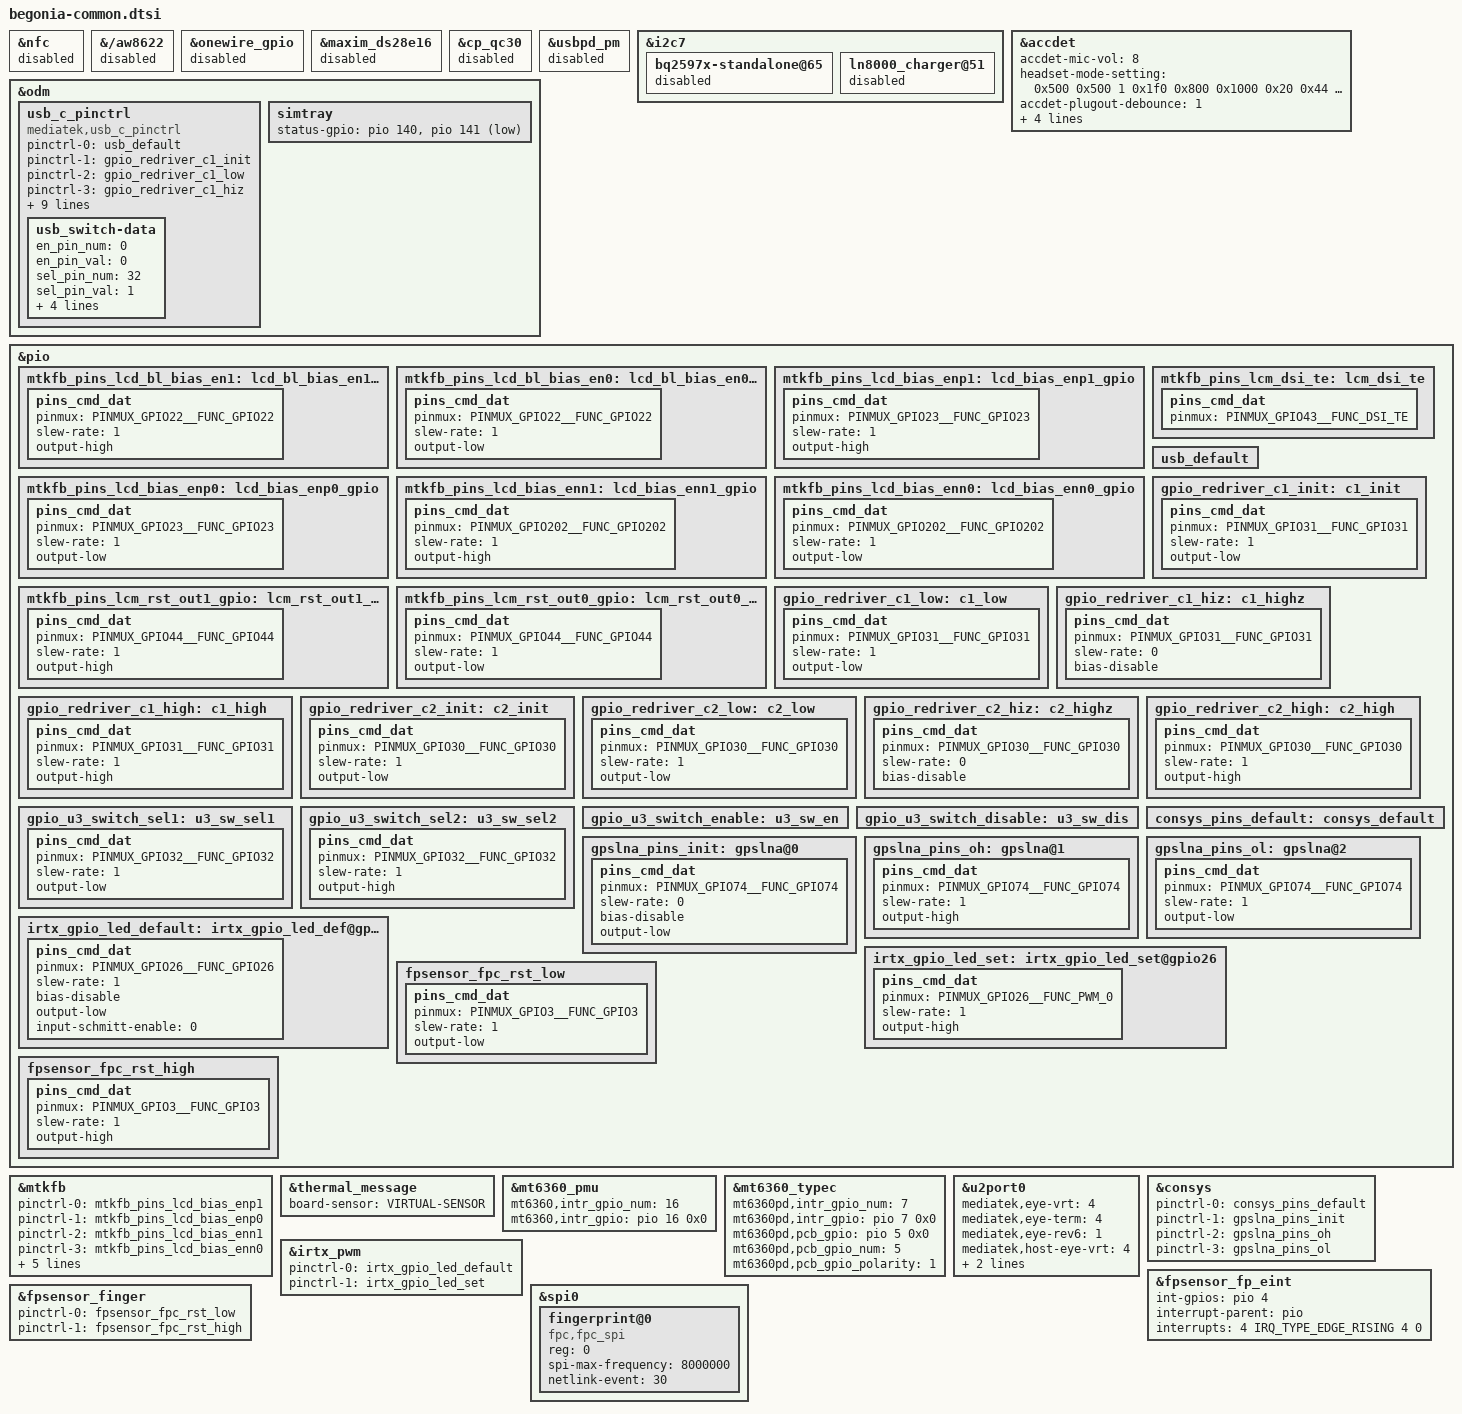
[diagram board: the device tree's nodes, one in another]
// SPDX-License-Identifier: GPL-2.0
#include <dt-bindings/interrupt-controller/irq.h>
#include <dt-bindings/interrupt-controller/arm-gic.h>
#include <dt-bindings/pinctrl/mt6785-pinfunc.h>

&nfc {
	status = "disabled";
};

&{/aw8622} {
	status = "disabled";
};

&onewire_gpio {
	status = "disabled";
};

&maxim_ds28e16 {
	status = "disabled";
};

&cp_qc30 {
	status = "disabled";
};

&usbpd_pm {
	status = "disabled";
};

&i2c7 {
	bq2597x-standalone@65 {
		status = "disabled";
	};

	ln8000_charger@51 {
		status = "disabled";
	};
};

&accdet {
	accdet-mic-vol = <8>;
	headset-mode-setting = <0x500 0x500 1 0x1f0
				0x800 0x1000 0x20 0x44
				0x4 0x1
				0x5 0x3 0x3 0x7 0xe>;
	accdet-plugout-debounce = <1>;
	accdet-mic-mode = <2>;
	headset-three-key-threshold = <0 80 220 400>;
	headset-four-key-threshold = <0 58 121 192 400>;
	eint_use_ext_res = <4>;
	status = "okay";
};

&odm {
	usb_c_pinctrl: usb_c_pinctrl {
		compatible = "mediatek,usb_c_pinctrl";
	};

	simtray {
		status-gpio = <&pio 140 0>,
			      <&pio 141 1>;
	};
};

&pio {
	mtkfb_pins_lcd_bl_bias_en1: lcd_bl_bias_en1_gpio {
		pins_cmd_dat {
			pinmux = <PINMUX_GPIO22__FUNC_GPIO22>;
			slew-rate = <1>;
			output-high;
		};
	};

	mtkfb_pins_lcd_bl_bias_en0: lcd_bl_bias_en0_gpio {
		pins_cmd_dat {
			pinmux = <PINMUX_GPIO22__FUNC_GPIO22>;
			slew-rate = <1>;
			output-low;
		};
	};

	mtkfb_pins_lcd_bias_enp1: lcd_bias_enp1_gpio {
		pins_cmd_dat {
			pinmux = <PINMUX_GPIO23__FUNC_GPIO23>;
			slew-rate = <1>;
			output-high;
		};
	};

	mtkfb_pins_lcd_bias_enp0: lcd_bias_enp0_gpio {
		pins_cmd_dat {
			pinmux = <PINMUX_GPIO23__FUNC_GPIO23>;
			slew-rate = <1>;
			output-low;
		};
	};

	mtkfb_pins_lcd_bias_enn1: lcd_bias_enn1_gpio {
		pins_cmd_dat {
			pinmux = <PINMUX_GPIO202__FUNC_GPIO202>;
			slew-rate = <1>;
			output-high;
		};
	};

	mtkfb_pins_lcd_bias_enn0: lcd_bias_enn0_gpio {
		pins_cmd_dat {
			pinmux = <PINMUX_GPIO202__FUNC_GPIO202>;
			slew-rate = <1>;
			output-low;
		};
	};

	mtkfb_pins_lcm_rst_out1_gpio: lcm_rst_out1_gpio {
		pins_cmd_dat {
			pinmux = <PINMUX_GPIO44__FUNC_GPIO44>;
			slew-rate = <1>;
			output-high;
		};
	};

	mtkfb_pins_lcm_rst_out0_gpio: lcm_rst_out0_gpio {
		pins_cmd_dat {
			pinmux = <PINMUX_GPIO44__FUNC_GPIO44>;
			slew-rate = <1>;
			output-low;
		};
	};

	mtkfb_pins_lcm_dsi_te: lcm_dsi_te {
		pins_cmd_dat {
			pinmux = <PINMUX_GPIO43__FUNC_DSI_TE>;
		};
	};
};

&mtkfb {
	pinctrl-names = "lcd_bias_enp1_gpio", "lcd_bias_enp0_gpio",
		"lcd_bias_enn1_gpio", "lcd_bias_enn0_gpio",
		"lcm_rst_out1_gpio", "lcm_rst_out0_gpio",
		"mode_te_te", "lcd_bl_bias_en1", "lcd_bl_bias_en0";
	pinctrl-0 = <&mtkfb_pins_lcd_bias_enp1>;
	pinctrl-1 = <&mtkfb_pins_lcd_bias_enp0>;
	pinctrl-2 = <&mtkfb_pins_lcd_bias_enn1>;
	pinctrl-3 = <&mtkfb_pins_lcd_bias_enn0>;
	pinctrl-4 = <&mtkfb_pins_lcm_rst_out1_gpio>;
	pinctrl-5 = <&mtkfb_pins_lcm_rst_out0_gpio>;
	pinctrl-6 = <&mtkfb_pins_lcm_dsi_te>;
	pinctrl-7 = <&mtkfb_pins_lcd_bl_bias_en1>;
	pinctrl-8 = <&mtkfb_pins_lcd_bl_bias_en0>;
	status = "okay";
};

&thermal_message {
	board-sensor = "VIRTUAL-SENSOR";
};

&mt6360_pmu {
	mt6360,intr_gpio_num = <16>;
	mt6360,intr_gpio = <&pio 16 0x0>;
};

&mt6360_typec {
	mt6360pd,intr_gpio_num = <7>;
	mt6360pd,intr_gpio = <&pio 7 0x0>;
	mt6360pd,pcb_gpio = <&pio 5 0x0>;
	mt6360pd,pcb_gpio_num = <5>;
	mt6360pd,pcb_gpio_polarity = <1>;
};

&u2port0 {
	mediatek,eye-vrt = <4>;
	mediatek,eye-term = <4>;
	mediatek,eye-rev6 = <1>;
	mediatek,host-eye-vrt = <4>;
	mediatek,host-eye-term = <4>;
	mediatek,host-eye-rev6 = <1>;
};

&pio {
	usb_default: usb_default {
	};

	gpio_redriver_c1_init: c1_init {
		pins_cmd_dat {
			pinmux = <PINMUX_GPIO31__FUNC_GPIO31>;
			slew-rate = <1>;
			output-low;
		};
	};

	gpio_redriver_c1_low: c1_low {
		pins_cmd_dat {
			pinmux = <PINMUX_GPIO31__FUNC_GPIO31>;
			slew-rate = <1>;
			output-low;
		};
	};

	gpio_redriver_c1_hiz: c1_highz {
		pins_cmd_dat {
			pinmux = <PINMUX_GPIO31__FUNC_GPIO31>;
			slew-rate = <0>;
			bias-disable;
		};
	};

	gpio_redriver_c1_high: c1_high {
		pins_cmd_dat {
			pinmux = <PINMUX_GPIO31__FUNC_GPIO31>;
			slew-rate = <1>;
			output-high;
		};
	};

	gpio_redriver_c2_init: c2_init {
		pins_cmd_dat {
			pinmux = <PINMUX_GPIO30__FUNC_GPIO30>;
			slew-rate = <1>;
			output-low;
		};
	};

	gpio_redriver_c2_low: c2_low {
		pins_cmd_dat {
			pinmux = <PINMUX_GPIO30__FUNC_GPIO30>;
			slew-rate = <1>;
			output-low;
		};
	};

	gpio_redriver_c2_hiz: c2_highz {
		pins_cmd_dat {
			pinmux = <PINMUX_GPIO30__FUNC_GPIO30>;
			slew-rate = <0>;
			bias-disable;
		};
	};

	gpio_redriver_c2_high: c2_high {
		pins_cmd_dat {
			pinmux = <PINMUX_GPIO30__FUNC_GPIO30>;
			slew-rate = <1>;
			output-high;
		};
	};

	gpio_u3_switch_sel1: u3_sw_sel1 {
		pins_cmd_dat {
			pinmux = <PINMUX_GPIO32__FUNC_GPIO32>;
			slew-rate = <1>;
			output-low;
		};
	};

	gpio_u3_switch_sel2: u3_sw_sel2 {
		pins_cmd_dat {
			pinmux = <PINMUX_GPIO32__FUNC_GPIO32>;
			slew-rate = <1>;
			output-high;
		};
	};

	gpio_u3_switch_enable: u3_sw_en {
	};

	gpio_u3_switch_disable: u3_sw_dis {
	};
};

&usb_c_pinctrl {
	pinctrl-names = "usb_default",
		"redrv_c1_init",
		"redrv_c1_low",
		"redrv_c1_hiz",
		"redrv_c1_high",
		"redrv_c2_init",
		"redrv_c2_low",
		"redrv_c2_hiz",
		"redrv_c2_high",
		"switch_sel1",
		"switch_sel2",
		"switch_enable",
		"switch_disable";
	pinctrl-0 = <&usb_default>;
	pinctrl-1 = <&gpio_redriver_c1_init>;
	pinctrl-2 = <&gpio_redriver_c1_low>;
	pinctrl-3 = <&gpio_redriver_c1_hiz>;
	pinctrl-4 = <&gpio_redriver_c1_high>;
	pinctrl-5 = <&gpio_redriver_c2_init>;
	pinctrl-6 = <&gpio_redriver_c2_low>;
	pinctrl-7 = <&gpio_redriver_c2_hiz>;
	pinctrl-8 = <&gpio_redriver_c2_high>;
	pinctrl-9 = <&gpio_u3_switch_sel1>;
	pinctrl-10 = <&gpio_u3_switch_sel2>;
	pinctrl-11 = <&gpio_u3_switch_enable>;
	pinctrl-12 = <&gpio_u3_switch_disable>;
	status = "okay";

	usb_switch-data {
		en_pin_num = <0>;
		en_pin_val = <0>;
		sel_pin_num = <32>;
		sel_pin_val = <1>;
		c1_pin_num = <31>;
		c1_pin_val = <2>;
		c2_pin_num = <30>;
		c2_pin_val = <1>;
	};
};

&pio {
	consys_pins_default: consys_default {
	};

	gpslna_pins_init: gpslna@0 {
		pins_cmd_dat {
			pinmux = <PINMUX_GPIO74__FUNC_GPIO74>;
			slew-rate = <0>;
			bias-disable;
			output-low;
		};
	};

	gpslna_pins_oh: gpslna@1 {
		pins_cmd_dat {
			pinmux = <PINMUX_GPIO74__FUNC_GPIO74>;
			slew-rate = <1>;
			output-high;
		};
	};

	gpslna_pins_ol: gpslna@2 {
		pins_cmd_dat {
			pinmux = <PINMUX_GPIO74__FUNC_GPIO74>;
			slew-rate = <1>;
			output-low;
		};
	};
};

&consys {
	pinctrl-names = "default", "gps_lna_state_init",
		"gps_lna_state_oh", "gps_lna_state_ol";
	pinctrl-0 = <&consys_pins_default>;
	pinctrl-1 = <&gpslna_pins_init>;
	pinctrl-2 = <&gpslna_pins_oh>;
	pinctrl-3 = <&gpslna_pins_ol>;
	status = "okay";
};

&irtx_pwm {
	pinctrl-names = "irtx_gpio_led_default", "irtx_gpio_led_set";
	pinctrl-0 = <&irtx_gpio_led_default>;
	pinctrl-1 = <&irtx_gpio_led_set>;
	status = "okay";
};

&pio {
	irtx_gpio_led_default: irtx_gpio_led_def@gpio26 {
		pins_cmd_dat {
			pinmux = <PINMUX_GPIO26__FUNC_GPIO26>;
			slew-rate = <1>;
			bias-disable;
			output-low;
			input-schmitt-enable = <0>;
		};
	};

	irtx_gpio_led_set: irtx_gpio_led_set@gpio26 {
		pins_cmd_dat {
			pinmux = <PINMUX_GPIO26__FUNC_PWM_0>;
			slew-rate = <1>;
			output-high;
		};
	};
};

&fpsensor_fp_eint {
	int-gpios = <&pio 4 0>;
	interrupt-parent = <&pio>;
	interrupts = <4 IRQ_TYPE_EDGE_RISING 4 0>;
	status = "okay";
};

&pio {
	fpsensor_fpc_rst_low: fpsensor_fpc_rst_low {
		pins_cmd_dat {
			pinmux = <PINMUX_GPIO3__FUNC_GPIO3>;
			slew-rate = <1>;
			output-low;
		};
	};

	fpsensor_fpc_rst_high: fpsensor_fpc_rst_high {
		pins_cmd_dat {
			pinmux = <PINMUX_GPIO3__FUNC_GPIO3>;
			slew-rate = <1>;
			output-high;
		};
	};
};

&fpsensor_finger {
	pinctrl-names = "fpsensor_fpc_rst_low", "fpsensor_fpc_rst_high";
	pinctrl-0 = <&fpsensor_fpc_rst_low>;
	pinctrl-1 = <&fpsensor_fpc_rst_high>;
	status = "okay";
};

&spi0 {
	#address-cells = <1>;
	#size-cells = <0>;

	fingerprint@0 {
		compatible = "fpc,fpc_spi";
		reg = <0>;
		spi-max-frequency = <8000000>;
		netlink-event = <30>;
		status = "okay";
	};
};
